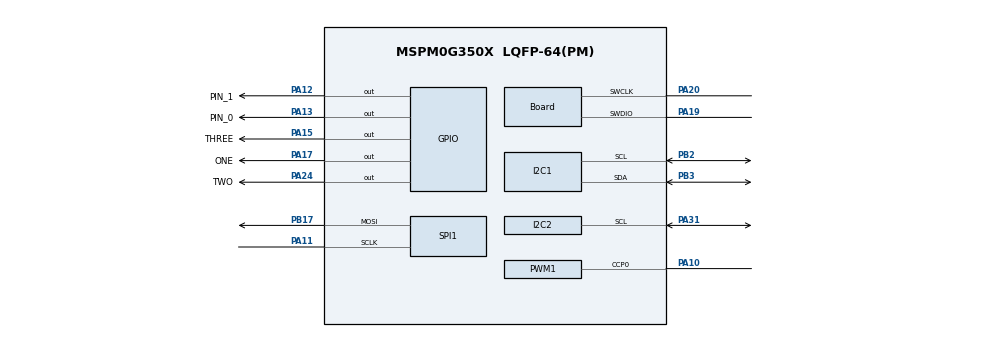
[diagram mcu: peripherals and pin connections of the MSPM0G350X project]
/**
 * @cliArgs --device "MSPM0G350X" --part "Default" --package "LQFP-64(PM)" --product "mspm0_sdk@2.03.00.08"
 * @versions {"tool":"1.22.0+3893"}
 */

/**
 * Import the modules used in this configuration.
 */
const GPIO          = scripting.addModule("/ti/driverlib/GPIO", {}, false);
const GPIO1         = GPIO.addInstance();
const GPIO2         = GPIO.addInstance();
const I2C           = scripting.addModule("/ti/driverlib/I2C", {}, false);
const I2C1          = I2C.addInstance();
const I2C2          = I2C.addInstance();
const PWM           = scripting.addModule("/ti/driverlib/PWM", {}, false);
const PWM1          = PWM.addInstance();
const SPI           = scripting.addModule("/ti/driverlib/SPI", {}, false);
const SPI1          = SPI.addInstance();
const SYSCTL        = scripting.addModule("/ti/driverlib/SYSCTL");
const TIMER         = scripting.addModule("/ti/driverlib/TIMER", {}, false);
const TIMER1        = TIMER.addInstance();
const TIMER2        = TIMER.addInstance();
const ProjectConfig = scripting.addModule("/ti/project_config/ProjectConfig");

/**
 * Write custom configuration values to the imported modules.
 */
GPIO1.$name                         = "PWR";
GPIO1.port                          = "PORTA";
GPIO1.associatedPins.create(2);
GPIO1.associatedPins[0].$name       = "PIN_0";
GPIO1.associatedPins[0].pin.$assign = "PA13";
GPIO1.associatedPins[1].$name       = "PIN_1";
GPIO1.associatedPins[1].pin.$assign = "PA12";

const Board                       = scripting.addModule("/ti/driverlib/Board", {}, false);
Board.peripheral.$assign          = "DEBUGSS";
Board.peripheral.swclkPin.$assign = "PA20";
Board.peripheral.swdioPin.$assign = "PA19";

GPIO2.$name                          = "SONGS";
GPIO2.port                           = "PORTA";
GPIO2.associatedPins.create(3);
GPIO2.associatedPins[0].$name        = "ONE";
GPIO2.associatedPins[0].initialValue = "SET";
GPIO2.associatedPins[0].pin.$assign  = "PA17";
GPIO2.associatedPins[1].$name        = "TWO";
GPIO2.associatedPins[1].initialValue = "SET";
GPIO2.associatedPins[1].pin.$assign  = "PA24";
GPIO2.associatedPins[2].$name        = "THREE";
GPIO2.associatedPins[2].initialValue = "SET";
GPIO2.associatedPins[2].pin.$assign  = "PA15";

I2C1.basicEnableController             = true;
I2C1.basicControllerBusSpeed           = 400000;
I2C1.advControllerTXFIFOTRIG           = "BYTES_1";
I2C1.intController                     = ["ARBITRATION_LOST","NACK","RXFIFO_TRIGGER","RX_DONE","TX_DONE"];
I2C1.$name                             = "I2C";
I2C1.advAnalogGlitchFilter             = "DISABLED";
I2C1.basicControllerStandardBusSpeed   = "Fast";
I2C1.peripheral.$assign                = "I2C1";
I2C1.peripheral.sdaPin.$assign         = "PB3";
I2C1.peripheral.sclPin.$assign         = "PB2";
I2C1.sdaPinConfig.$name                = "ti_driverlib_gpio_GPIOPinGeneric0";
I2C1.sdaPinConfig.hideOutputInversion  = scripting.forceWrite(false);
I2C1.sdaPinConfig.onlyInternalResistor = scripting.forceWrite(false);
I2C1.sdaPinConfig.passedPeripheralType = scripting.forceWrite("Digital");
I2C1.sclPinConfig.$name                = "ti_driverlib_gpio_GPIOPinGeneric1";
I2C1.sclPinConfig.hideOutputInversion  = scripting.forceWrite(false);
I2C1.sclPinConfig.onlyInternalResistor = scripting.forceWrite(false);
I2C1.sclPinConfig.passedPeripheralType = scripting.forceWrite("Digital");

I2C2.$name                           = "I2C_0";
I2C2.basicEnableController           = true;
I2C2.basicControllerStandardBusSpeed = "Fast";
I2C2.advAnalogGlitchFilter           = "DISABLED";
I2C2.advControllerTXFIFOTRIG         = "BYTES_1";
I2C2.intController                   = ["NACK","RXFIFO_TRIGGER","RX_DONE","TX_DONE"];
I2C2.peripheral.sclPin.$assign       = "PA31";
I2C2.sdaPinConfig.$name              = "ti_driverlib_gpio_GPIOPinGeneric5";
I2C2.sclPinConfig.$name              = "ti_driverlib_gpio_GPIOPinGeneric6";

PWM1.$name                      = "PWM_0";
PWM1.timerCount                 = 8000;
PWM1.ccIndex                    = [0];
PWM1.peripheral.$assign         = "TIMA1";
PWM1.peripheral.ccp0Pin.$assign = "PA10";
PWM1.PWM_CHANNEL_0.$name        = "ti_driverlib_pwm_PWMTimerCC0";
PWM1.PWM_CHANNEL_0.ccValue      = 4000;
PWM1.PWM_CHANNEL_0.dutyCycle    = 50;
PWM1.ccp0PinConfig.$name        = "ti_driverlib_gpio_GPIOPinGeneric4";

SPI1.$name                      = "SPI_0";
SPI1.targetBitRate              = 2500000;
SPI1.frameFormat                = "MOTO3";
SPI1.polarity                   = "1";
SPI1.phase                      = "1";
SPI1.rxFifoThreshold            = "DL_SPI_RX_FIFO_LEVEL_ONE_FRAME";
SPI1.txFifoThreshold            = "DL_SPI_TX_FIFO_LEVEL_EMPTY";
SPI1.direction                  = "PICO";
SPI1.enabledInterrupts          = ["TX"];
SPI1.peripheral.$assign         = "SPI0";
SPI1.peripheral.sclkPin.$assign = "PA11";
SPI1.peripheral.mosiPin.$assign = "PB17";
SPI1.sclkPinConfig.$name        = "ti_driverlib_gpio_GPIOPinGeneric2";
SPI1.mosiPinConfig.$name        = "ti_driverlib_gpio_GPIOPinGeneric3";

SYSCTL.forceDefaultClkConfig = true;
SYSCTL.clockTreeEn           = true;

TIMER1.$name           = "TIMER_1";
TIMER1.timerClkSrc     = "LFCLK";
TIMER1.timerMode       = "PERIODIC_UP";
TIMER1.timerStartTimer = true;
TIMER1.timerPeriod     = "20000 us";

TIMER2.$name = "TIMER_0";

ProjectConfig.genLibDrivers = true;

/**
 * Pinmux solution for unlocked pins/peripherals. This ensures that minor changes to the automatic solver in a future
 * version of the tool will not impact the pinmux you originally saw.  These lines can be completely deleted in order to
 * re-solve from scratch.
 */
I2C2.peripheral.$suggestSolution        = "I2C0";
I2C2.peripheral.sdaPin.$suggestSolution = "PA0";
TIMER1.peripheral.$suggestSolution      = "TIMG0";
TIMER2.peripheral.$suggestSolution      = "TIMA0";
